# GD32A72_A74x register map
File version: 1.0
CPU: CM7 r2p1, little endian, MPU, FPU, DSP, 4 interrupt priority bits
Registers are 32-bit, read-write, reset 0x0 unless marked. A register's access mark holds for its fields unless they carry their own. Offsets are from the block's base; [hi:lo] are bit positions; {n}, {i} and the like mark numbered series; 'fields as' and 'values as' point back to an identical list.

## FMC — Flash memory controller
Base 0x49002000
0x00 WS reset 0x1 — Wait state register
  [2:0] WSCNT — Wait state counter
0x04 SPCKEY wo — Unlock SPC protect key register
  [31:0] SPCKEY — SPC unlock key
0x14 KEY0 wo — Unlock key register 0
  [31:0] KEY — FMC_CTL0 unlock key
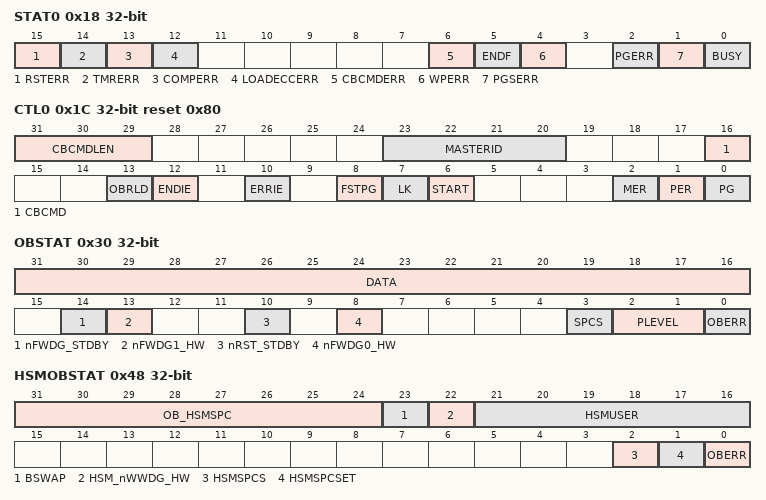
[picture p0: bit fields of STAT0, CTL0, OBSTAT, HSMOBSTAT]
0x18 STAT0 access per field — Status register 0
  [15] RSTERR rw — Reset error during erase / program flag
  [14] TMRERR ro — TMR error flag bit
  [13] COMPERR rw — Complement error in writing data
  [12] LOADECCERR rw — ECC error when load
  [6] CBCMDERR rw — The checked area by the check blank command is all 0xFF or not
  [5] ENDF rw — End of operation flag bit
  [4] WPERR rw — Erase / Program protection error flag bit
  [2] PGERR rw — Program error flag bit
  [1] PGSERR rw — Program sequence error flag bit
  [0] BUSY ro — The flash busy flag
0x1C CTL0 access per field reset 0x80 — Control register 0
  [31:29] CBCMDLEN rw — CBCMD read length 2^(CBCMDLEN)
  [23:20] MASTERID ro — The Master ID of unlock FMC_CTL0 register
  [16] CBCMD rw — The command to check the selected area is blank or not
  [13] OBRLD rw — Option byte reload bit
  [12] ENDIE rw — End of operation interrupt enable bit
  [10] ERRIE rw — Error interrupt enable bit
  [8] FSTPG rw — Main flash fast program command bit
  [7] LK rw — FMC_CTL0 lock bit
  [6] START rw — Send command to FMC bit
  [2] MER rw — Main flash mass erase command bit
  [1] PER rw — Main flash page erase command bit
  [0] PG rw — Main flash program command bit
0x20 ADDR0 — Address register 0
  [31:0] ADDR — Flash erase / program command address bits
0x24 WDATAL0 — Write data low 0 register
  [31:0] WDATA — Flash program command write data bits
0x28 WDATAH0 — Write data high 0 register
  [31:0] WDATA — Flash program command write data bits
0x30 OBSTAT ro — Option byte status register
  [31:16] DATA — Store OB_DATA[15:0] of option byte block after system reset
  [14] nFWDG_STDBY — Free watchdog count mode configuration bit in standby mode
  [13] nFWDG1_HW — Free watchdog 1 mode configuration bit
  [10] nRST_STDBY — Reset mode configuration bit when entering standby mode
  [8] nFWDG0_HW — Free watchdog 0 mode configuration bit
  [3] SPCS — Security protection state
  [2:1] PLEVEL — Security Protection level
  [0] OBERR — Option byte read error bit
0x34 WP0 ro — Erase / Program protection register 0
  [31:0] BK0WP — Store OB_BK0WP[31:0] of HOST option bytes block after system reset
0x38 WP1 ro — Erase / Program protection register 1
  [31:0] BK1WP — Store OB_BK1WP[31:0] of HOST option bytes block after system reset
0x3C WP2 ro — Erase / Program protection register 2
  [7:0] DFWP — Store OB_DFWP[7:0] of option bytes block after system reset
0x40 OBUSER1_0 ro — option byte USER1 register 0
  [31:0] USER1 — store OB_USER1[31:0] of option bytes block after system reset
0x44 OBUSER1_1 ro — option byte USER1 register 1
  [31:0] USER1 — store OB_USER1[63:32] of option bytes block after system reset
0x48 HSMOBSTAT access per field — HSM option byte status register
  [31:24] OB_HSMSPC ro — HSM option byte security protection code
  [23] BSWAP ro — Bank swap
  [22] HSM_nWWDG_HW ro — HSM window watch dog mode configuration bit
  [21:16] HSMUSER ro — Store HSM OB_USER byte of option byte block after system reset
  [2] HSMSPCS ro — HSM security protection state
  [1] HSMSPCSET rw — HSM security protection set
  [0] OBERR ro — HSM option byte read error bit
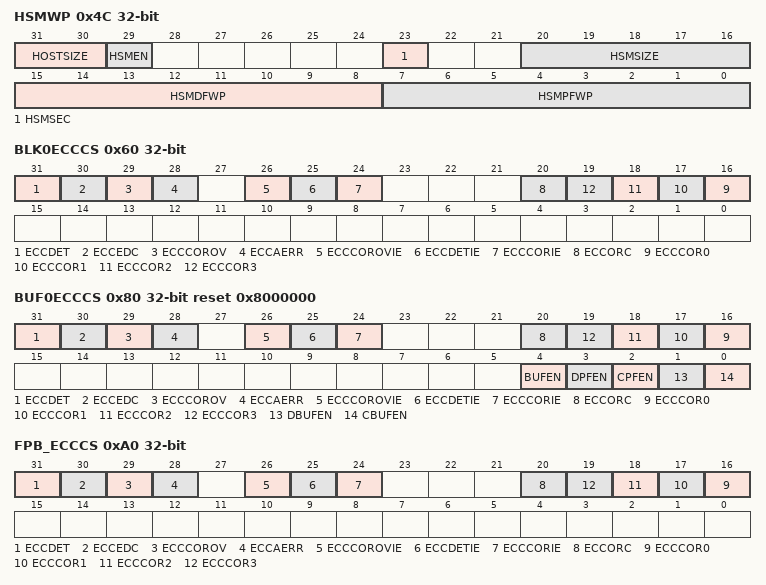
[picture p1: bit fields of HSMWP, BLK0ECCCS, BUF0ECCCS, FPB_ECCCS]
0x4C HSMWP ro — HSM Erase / Program protection register
  [31:30] HOSTSIZE — HOST bank 0 / bank 1 size
  [29] HSMEN — HSM enable
  [23] HSMSEC — HSM SECURITY
  [20:16] HSMSIZE — HSM bank 0 / bank 1 size
  [15:8] HSMDFWP — Store OB_HSMDFWP [7:0] of HSM option bytes block after system reset
  [7:0] HSMPFWP — Store OB_HSMPFWP [7:0] of HSM option bytes block after system reset
0x60 BLK0ECCCS access per field — Block 0 ECC control and status register
  [31] ECCDET rw — Two bit errors detect flag
  [30] ECCEDC rw — EDC after ECC checker error flag
  [29] ECCCOROV rw — More than 4 one bit error detected
  [28] ECCAERR rw — ECC one bit error in address stage
  [26] ECCCOROVIE rw — More than 4 one bit error detect interrupt enable
  [25] ECCDETIE rw — Two bit errors detect interrupt enable
  [24] ECCCORIE rw — One bit error correct interrupt enable
  [20] ECCORC rw — Write 1 to clear ECCORx
  [n+16] ECCCOR{n} ro (n=0..3) — One bit error detected and correct flag
0x64 BLK0UCECCADDR ro — Block 0 uncorrectable ECC address register
  [21:0] ECCADDR — The offset address of double word where an uncorrectable ECC error is detected
{0x68+4i} BLK0CECCADDR{i} ro (i=0..3) — Block 0 correctable ECC address {i} register
  [21:0] ECCADDR — The offset address of double word where an correctable ECC error is detected
0x80 BUF0ECCCS access per field reset 0x8000000 — Buffer 0 control and status register
  [31] ECCDET rw — Two bit errors detect flag
  [30] ECCEDC rw — EDC after ECC checker error flag
  [29] ECCCOROV rw — More than 4 one bit error detected
  [28] ECCAERR rw — ECC one bit error in address stage
  [26] ECCCOROVIE rw — More than 4 one bit error detect interrupt enable
  [25] ECCDETIE rw — Two bit errors detect interrupt enable
  [24] ECCCORIE rw — One bit error correct interrupt enable
  [20] ECCORC rw — Write 1 to clear ECCORx
  [n+16] ECCCOR{n} ro (n=0..3) — One bit error detected and correct flag
  [4] BUFEN rw — Buffers enable
  [3] DPFEN rw — Data prefetch enable
  [2] CPFEN rw — Code prefetch enable
  [1] DBUFEN rw — Read data buffers enable
  [0] CBUFEN rw — Read code buffers enable
0x84 BUF0UCECCADDR ro — Buffer 0 uncorrectable ECC address register
  [23:0] ECCADDR — The offset address of double word where an uncorrectable ECC error is detected
{0x88+4i} BUF0CECCADDR{i} ro (i=0..3) — Buffer 0 correctable ECC address{i}
  [23:0] ECCADDR — The offset address of double word where an correctable ECC error is detected
0xA0 FPB_ECCCS access per field — Fast program buffer ECC control and status register
  fields as BLK0ECCCS
0xA4 FPB_UCECCADDR ro — Fast program buffer uncorrectable ECC Address register
  [9:0] ECCADDR — The offset address of double word where an uncorrectable ECC error is detected
{0xA8+4i} FPB_CECCADDR{i} ro (i=0..3) — Fast program buffer correctable ECC Address{i} register
  [9:0] ECCADDR — The offset address of double word where an correctable ECC error is detected
0xD0 PID0 ro — Product ID register 0
  [31:0] PID — Product reserved ID code register 0
0xD4 PID1 ro — Product ID register 1
  [31:0] PID — Product reserved ID code register 1
0x114 KEY1 wo — Unlock key register 1
  [31:0] KEY — FMC_CTLx unlock key
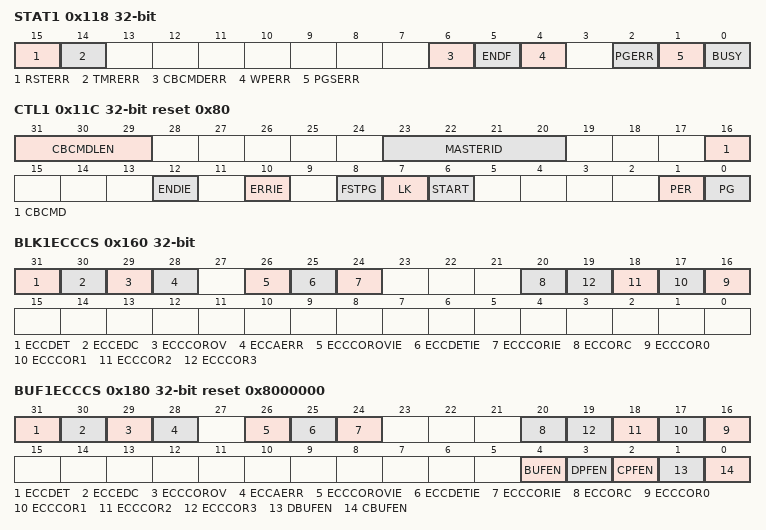
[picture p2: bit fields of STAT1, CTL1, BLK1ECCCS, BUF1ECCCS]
0x118 STAT1 access per field — Status register 1
  [15] RSTERR rw — Reset error during erase / program flag
  [14] TMRERR ro — TMR error flag bit
  [6] CBCMDERR rw — The checked area by the check blank command is all 0xFF or not
  [5] ENDF rw — End of operation flag bit
  [4] WPERR rw — Erase / Program protection error flag bit
  [2] PGERR rw — Program error flag bit
  [1] PGSERR rw — Program sequence error flag bit
  [0] BUSY ro — The flash busy flag
0x11C CTL1 access per field reset 0x80 — Control register 1
  [31:29] CBCMDLEN rw — CBCMD read length 2^(CBCMDLEN)
  [23:20] MASTERID ro — The Master ID of unlock FMC_CTLx register
  [16] CBCMD rw — The command to check the selected area is blank or not
  [12] ENDIE rw — End of operation interrupt enable bit
  [10] ERRIE rw — Error interrupt enable bit
  [8] FSTPG rw — Main flash fast program command bit
  [7] LK rw — FMC_CTL1 lock bit
  [6] START rw — Send command to FMC bit
  [1] PER rw — Main flash page erase command bit
  [0] PG rw — Main flash program command bit
0x120 ADDR1 — Address register 1
  [31:0] ADDR — Flash erase / program command address bits
0x124 WDATAL1 — Write data low 1 register
  [31:0] WDATA — Flash program command write data bits
0x128 WDATAH1 — Write data high 1 register
  [31:0] WDATA — Flash program command write data bits
0x160 BLK1ECCCS access per field — Block1 ECC control and status register
  [31] ECCDET rw — Two bit errors detect flag
  [30] ECCEDC rw — EDC after ECC checker error flag
  [29] ECCCOROV rw — More than 4 one bit error detected
  [28] ECCAERR rw — ECC oe bit error in address stage
  [26] ECCCOROVIE rw — More than 4 one bit error detect interrupt enable
  [25] ECCDETIE rw — Two bit errors detect interrupt enable
  [24] ECCCORIE rw — One bit error correct interrupt enable
  [20] ECCORC rw — Write 1 to clear ECCORx
  [n+16] ECCCOR{n} ro (n=0..3) — One bit error detected and correct flag
{0x64+0x100*i} BLK{i}UCECCADDR ro (i=1..3) — Block{i} uncorrectable ECC address register
  fields as BLK0UCECCADDR
{0x168+4i} BLK1CECCADDR{i} ro (i=0..3) — Block1 correctable ECC address {i} register
  fields as BLK0CECCADDR0
0x180 BUF1ECCCS access per field reset 0x8000000 — Buffer1 control and status register
  [31] ECCDET rw — Two bit errors detect flag
  [30] ECCEDC rw — EDC after ECC checker error flag
  [29] ECCCOROV rw — More than 4 one bit error detected
  [28] ECCAERR rw — ECC oe bit error in address stage
  [26] ECCCOROVIE rw — More than 4 one bit error detect interrupt enable
  [25] ECCDETIE rw — Two bit errors detect interrupt enable
  [24] ECCCORIE rw — One bit error correct interrupt enable
  [20] ECCORC rw — Write 1 to clear ECCORx
  [n+16] ECCCOR{n} ro (n=0..3) — One bit error detected and correct flag
  [4] BUFEN rw — Buffers enable
  [3] DPFEN rw — Data prefetch enable
  [2] CPFEN rw — Code prefetch enable
  [1] DBUFEN rw — Read data buffers enable
  [0] CBUFEN rw — Read code buffers enable
{0x84+0x100*i} BUF{i}UCECCADDR ro (i=1..3) — Buffer{i} uncorrectable ECC address register
  fields as BUF0UCECCADDR
{0x188+4i} BUF1CECCADDR{i} ro (i=0..3) — Buffer1 correctable ECC address{i}
  fields as BUF0CECCADDR0
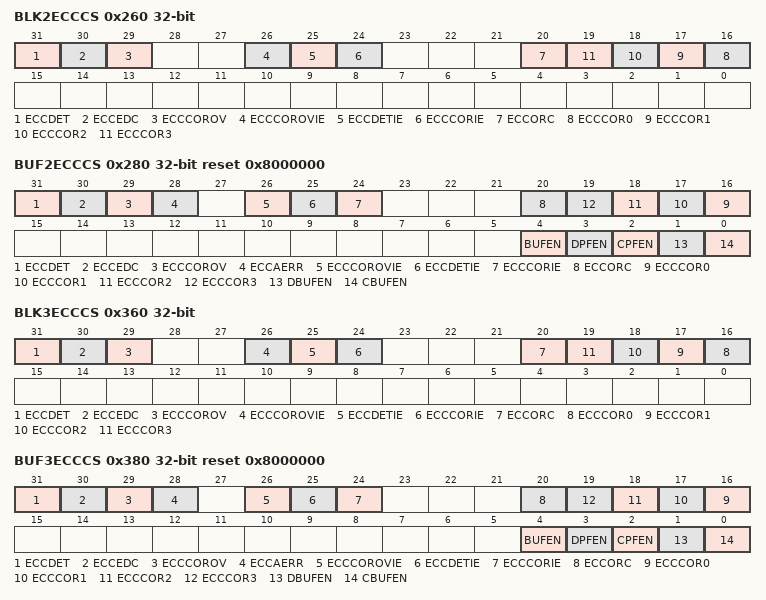
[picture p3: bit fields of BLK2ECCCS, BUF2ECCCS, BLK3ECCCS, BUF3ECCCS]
0x260 BLK2ECCCS access per field — Block2 ECC control and status register
  [31] ECCDET rw — Two bit errors detect flag
  [30] ECCEDC rw — EDC after ECC checker error flag
  [29] ECCCOROV rw — More than 4 one bit error detected
  [26] ECCCOROVIE rw — More than 4 one bit error detect interrupt enable
  [25] ECCDETIE rw — Two bit errors detect interrupt enable
  [24] ECCCORIE rw — One bit error correct interrupt enable
  [20] ECCORC rw — Write 1 to clear ECCORx
  [n+16] ECCCOR{n} ro (n=0..3) — One bit error detected and correct flag
{0x268+4i} BLK2CECCADDR{i} ro (i=0..3) — Block2 correctable ECC address {i} register
  fields as BLK0CECCADDR0
0x280 BUF2ECCCS access per field reset 0x8000000 — Buffer2 control and status register
  fields as BUF1ECCCS
{0x288+4i} BUF2CECCADDR{i} ro (i=0..3) — Buffer2 correctable ECC address{i}
  fields as BUF0CECCADDR0
0x360 BLK3ECCCS access per field — Block2 ECC control and status register
  fields as BLK2ECCCS
{0x368+4i} BLK3CECCADDR{i} ro (i=0..3) — Block3 correctable ECC address {i} register
  fields as BLK0CECCADDR0
0x380 BUF3ECCCS access per field reset 0x8000000 — Buffer3 control and status register
  fields as BUF0ECCCS
{0x388+4i} BUF3CECCADDR{i} ro (i=0..3) — Buffer3 correctable ECC address{i} register
  fields as BUF0CECCADDR0
